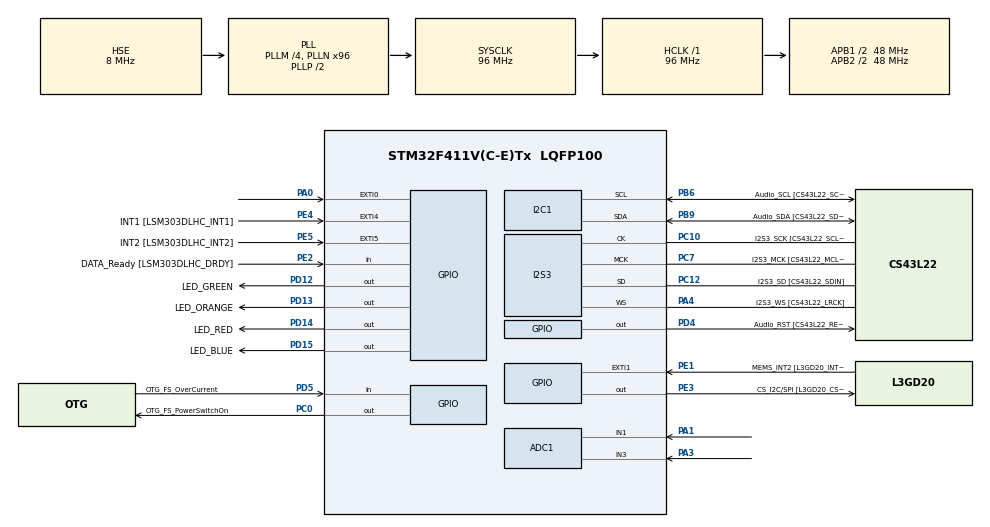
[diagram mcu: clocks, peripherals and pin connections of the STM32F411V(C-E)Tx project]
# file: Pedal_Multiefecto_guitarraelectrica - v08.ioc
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PD12.GPIO_Label=LED_GREEN
TIM2.Channel-Output\ Compare1\ No\ Output=TIM_CHANNEL_1
PC10.GPIO_PuPd=GPIO_NOPULL
PC12.Signal=I2S3_SD
PA14.GPIO_Label=SWCLK
PA6.GPIO_Label=SPI1_MISO [L3GD20_AS0/SDO]
PB6.GPIO_Label=Audio_SCL [CS43L22_SCL]
PC15-OSC32_OUT.GPIO_Label=PC15-OSC32_OUT
RCC.SYSCLKSource=RCC_SYSCLKSOURCE_PLLCLK
PD14.GPIO_Speed=GPIO_SPEED_FREQ_LOW
PA4.Mode=Half_Duplex_Master
RCC.APB2TimFreq_Value=96000000
PD4.Signal=GPIO_Output
Dma.ADC1.0.Direction=DMA_PERIPH_TO_MEMORY
PB6.Signal=I2C1_SCL
PC7.Signal=I2S3_MCK
PB6.Mode=I2C
PC3.Signal=I2S2_SD
PE5.Signal=GPXTI5
PE1.Signal=GPXTI1
Dma.ADC1.0.MemDataAlignment=DMA_MDATAALIGN_WORD
ADC1.ScanConvMode=ENABLE
I2S3.ErrorAudioFreq=0.0 %
Dma.ADC1.0.PeriphInc=DMA_PINC_DISABLE
NVIC.TIM2_IRQn=true\:0\:0\:false\:false\:true\:true\:true
PE4.GPIO_Label=INT1 [LSM303DLHC_INT1]
PE2.Signal=GPIO_Input
PD14.GPIO_PuPd=GPIO_NOPULL
ADC1.SamplingTime-0\#ChannelRegularConversion=ADC_SAMPLETIME_3CYCLES
Mcu.Package=LQFP100
PB9.Signal=I2C1_SDA
TIM2.Prescaler=1000-1
PD12.Signal=GPIO_Output
PA10.Signal=USB_OTG_FS_ID
PB9.GPIO_PuPd=GPIO_NOPULL
RCC.APB2CLKDivider=RCC_HCLK_DIV2
RCC.APB1TimFreq_Value=96000000
Dma.ADC1.0.FIFOMode=DMA_FIFOMODE_DISABLE
PC12.GPIO_PuPd=GPIO_NOPULL
PA4.GPIO_Label=I2S3_WS [CS43L22_LRCK]
ADC1.EOCSelection=ADC_EOC_SEQ_CONV
PD15.Signal=GPIO_Output
PC0.PinState=GPIO_PIN_SET
Dma.SPI3_TX.1.MemInc=DMA_MINC_ENABLE
I2S3.FullDuplexMode=I2S_FULLDUPLEXMODE_DISABLE
Dma.ADC1.0.Instance=DMA2_Stream0
ADC1.Rank-0\#ChannelRegularConversion=1
TIM3.Channel-Output\ Compare1\ No\ Output=TIM_CHANNEL_1
TIM3.AutoReloadPreload=TIM_AUTORELOAD_PRELOAD_ENABLE
PA9.GPIO_Label=VBUS_FS
PB6.GPIO_PuPd=GPIO_NOPULL
PH1\ -\ OSC_OUT.Mode=HSE-External-Oscillator
PA11.GPIO_Label=OTG_FS_DM
Dma.SPI3_TX.1.Priority=DMA_PRIORITY_LOW
PC0.Signal=GPIO_Output
RCC.APB1CLKDivider=RCC_HCLK_DIV2
PC14-OSC32_IN.Signal=RCC_OSC32_IN
I2S3.DataFormat=I2S_DATAFORMAT_16B_EXTENDED
PA0-WKUP.GPIO_ModeDefaultEXTI=GPIO_MODE_EVT_RISING
PA0-WKUP.Signal=GPXTI0
PC10.GPIO_Mode=GPIO_MODE_AF_PP
PE5.GPIO_ModeDefaultEXTI=GPIO_MODE_EVT_RISING
Dma.ADC1.0.Priority=DMA_PRIORITY_LOW
PA9.Signal=USB_OTG_FS_VBUS
Dma.SPI3_TX.1.MemDataAlignment=DMA_MDATAALIGN_WORD
I2S3.VirtualMode=I2S_MODE_MASTER
PC7.GPIO_PuPd=GPIO_NOPULL
PB10.Signal=I2S2_CK
PA5.Signal=SPI1_SCK
I2S3.AudioFreq=I2S_AUDIOFREQ_32K
PC12.Mode=Half_Duplex_Master
PH1\ -\ OSC_OUT.Signal=RCC_OSC_OUT
VP_TIM3_VS_no_output1.Mode=Output Compare1 No Output
PE1.GPIO_Label=MEMS_INT2 [L3GD20_INT2]
NVIC.TIM3_IRQn=true\:0\:0\:false\:false\:true\:true\:true
TIM3.OCMode_1=TIM_OCMODE_TIMING
ADC1.DMAContinuousRequests=ENABLE
TIM2.Period=96000-1
PA13.Mode=Serial_Wire
ADC1.ExternalTrigConv=ADC_EXTERNALTRIGCONV_T3_TRGO
PC7.GPIO_Label=I2S3_MCK [CS43L22_MCLK]
Dma.SPI3_TX.1.PeriphInc=DMA_PINC_DISABLE
PA4.Signal=I2S3_WS
PC12.GPIO_Mode=GPIO_MODE_AF_PP
ADC1.master=1
PA5.GPIO_Label=SPI1_SCK [L3GD20_SC/SPC]
PE5.GPIO_Label=INT2 [LSM303DLHC_INT2]
PC12.GPIO_Label=I2S3_SD [CS43L22_SDIN]
PA11.Signal=USB_OTG_FS_DM
ProjectManager.HeapSize=0x200
NVIC.PriorityGroup=NVIC_PRIORITYGROUP_0
PE3.Signal=GPIO_Output
TIM2.AutoReloadPreload=TIM_AUTORELOAD_PRELOAD_ENABLE
PC3.GPIO_Label=PDM_OUT [MP45DT02_DOUT]
I2S3.Instance=SPI$Index
PB6.GPIO_Speed=GPIO_SPEED_FREQ_LOW
Mcu.Family=STM32F4
RCC.CortexFreq_Value=96000000
PB6.GPIO_Mode=GPIO_MODE_AF_OD
ADC1.ContinuousConvMode=DISABLE
PD15.GPIO_Speed=GPIO_SPEED_FREQ_LOW
PC10.Signal=I2S3_CK
PC0.GPIO_Label=OTG_FS_PowerSwitchOn
PC10.GPIO_Speed=GPIO_SPEED_FREQ_LOW
ProjectManager.StackSize=0x400
PD13.Signal=GPIO_Output
PA12.Signal=USB_OTG_FS_DP
PH0\ -\ OSC_IN.Signal=RCC_OSC_IN
ADC1.Channel-3\#ChannelRegularConversion=ADC_CHANNEL_3
RCC.HCLKFreq_Value=96000000
SH.ADCx_IN3.0=ADC1_IN3,IN3
TIM3.Period=1500-1
TIM2.ClockDivision=TIM_CLOCKDIVISION_DIV1
NVIC.DMA2_Stream0_IRQn=true\:0\:0\:false\:false\:true\:false\:true
RCC.AHBFreq_Value=96000000
ADC1.Channel-0\#ChannelRegularConversion=ADC_CHANNEL_1
RCC.HSE_VALUE=8000000
VP_TIM2_VS_no_output1.Mode=Output Compare1 No Output
PA4.GPIO_PuPd=GPIO_NOPULL
PA4.GPIO_Speed=GPIO_SPEED_FREQ_LOW
PC14-OSC32_IN.Mode=LSE-External-Oscillator
PA14.Mode=Serial_Wire
TIM3.Prescaler=1-1
PA10.GPIO_Label=OTG_FS_ID
PC7.GPIO_Mode=GPIO_MODE_AF_PP
PE4.Signal=GPXTI4
PD13.GPIO_Label=LED_ORANGE
PA6.Signal=SPI1_MISO
PD5.GPIO_Label=OTG_FS_OverCurrent
PD15.GPIO_PuPd=GPIO_NOPULL
Dma.SPI3_TX.1.Direction=DMA_MEMORY_TO_PERIPH
SH.ADCx_IN1.0=ADC1_IN1,IN1
PB9.GPIO_Speed=GPIO_SPEED_FREQ_LOW
Dma.Request1=SPI3_TX
PC14-OSC32_IN.GPIO_Label=PC14-OSC32_IN
Dma.Request0=ADC1
PE2.GPIO_Label=DATA_Ready [LSM303DLHC_DRDY]
PA3.Signal=ADCx_IN3
PB3.GPIO_Label=SWO
RCC.PLLSourceVirtual=RCC_PLLSOURCE_HSE
PC15-OSC32_OUT.Mode=LSE-External-Oscillator
PD12.GPIO_Speed=GPIO_SPEED_FREQ_LOW
PD15.GPIO_Label=LED_BLUE
PB9.GPIO_Label=Audio_SDA [CS43L22_SDA]
PC10.GPIO_Label=I2S3_SCK [CS43L22_SCLK]
PC10.Mode=Half_Duplex_Master
PE4.GPIO_ModeDefaultEXTI=GPIO_MODE_EVT_RISING
Dma.SPI3_TX.1.FIFOMode=DMA_FIFOMODE_DISABLE
PD5.Signal=GPIO_Input
PE1.GPIO_ModeDefaultEXTI=GPIO_MODE_EVT_RISING
PA12.GPIO_Label=OTG_FS_DP
Dma.SPI3_TX.1.Instance=DMA1_Stream5
Dma.SPI3_TX.1.PeriphDataAlignment=DMA_PDATAALIGN_WORD
PA13.Signal=SYS_JTMS-SWDIO
Dma.ADC1.0.PeriphDataAlignment=DMA_PDATAALIGN_WORD
PH0\ -\ OSC_IN.Mode=HSE-External-Oscillator
Dma.SPI3_TX.1.Mode=DMA_CIRCULAR
ProjectManager.TargetToolchain=SW4STM32
PB10.GPIO_Label=CLK_IN [MP45DT02_CLK]
NVIC.DMA1_Stream5_IRQn=true\:0\:0\:false\:false\:true\:false\:true
Dma.ADC1.0.Mode=DMA_CIRCULAR
PB9.Mode=I2C
PC15-OSC32_OUT.Signal=RCC_OSC32_OUT
PA1.Signal=ADCx_IN1
board=STM32F411E-DISCO
PD13.GPIO_Speed=GPIO_SPEED_FREQ_LOW
PC7.GPIO_Speed=GPIO_SPEED_FREQ_LOW
RCC.VCOOutputFreq_Value=192000000
PB9.GPIO_Mode=GPIO_MODE_AF_OD
PA4.GPIO_Mode=GPIO_MODE_AF_PP
RCC.APB2Freq_Value=48000000
PD4.GPIO_Label=Audio_RST [CS43L22_RESET]
PD13.GPIO_PuPd=GPIO_NOPULL
PD14.GPIO_Label=LED_RED
ADC1.NbrOfConversion=2
Mcu.Name=STM32F411V(C-E)Tx
PA13.GPIO_Label=SWDIO
PH1\ -\ OSC_OUT.GPIO_Label=PH1-OSC_OUT
PD14.Signal=GPIO_Output
RCC.48MHZClocksFreq_Value=24000000
PB3.Signal=SYS_JTDO-SWO
RCC.SYSCLKFreq_VALUE=96000000
PA7.GPIO_Label=SPI1_MOSI [L3GD20_SDA/SDI/SDO]
ADC1.Rank-3\#ChannelRegularConversion=2
ADC1.SamplingTime-3\#ChannelRegularConversion=ADC_SAMPLETIME_3CYCLES
TIM3.TIM_MasterSlaveMode=TIM_MASTERSLAVEMODE_DISABLE
PA14.Signal=SYS_JTCK-SWCLK
Dma.ADC1.0.MemInc=DMA_MINC_ENABLE
RCC.HSI_VALUE=16000000
RCC.PLLQ=8
ADC1.NbrOfConversionFlag=1
I2S3.RealAudioFreq=32.001 KHz
RCC.PLLM=4
RCC.PLLN=96
PE3.GPIO_Label=CS_I2C/SPI [L3GD20_CS_I2C/SPI]
PH0\ -\ OSC_IN.GPIO_Label=PH0-OSC_IN
TIM3.TIM_MasterOutputTrigger=TIM_TRGO_UPDATE
PC7.Mode=Master_Clock_Activated
RCC.APB1Freq_Value=48000000
PC12.GPIO_Speed=GPIO_SPEED_FREQ_LOW
ADC1.ClockPrescaler=ADC_CLOCK_SYNC_PCLK_DIV2
RCC.PLLI2SN=213
PB12.Signal=I2S2_WS
PD12.GPIO_PuPd=GPIO_NOPULL
RCC.PLLI2SM=8
PA7.Signal=SPI1_MOSI

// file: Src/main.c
/* USER CODE BEGIN Header */
/**
  ******************************************************************************
  * @file           : main.c
  * @brief          : Main program body
  ******************************************************************************
  * @attention
  *
  * <h2><center>&copy; Copyright (c) 2020 STMicroelectronics.
  * All rights reserved.</center></h2>
  *
  * This software component is licensed by ST under Ultimate Liberty license
  * SLA0044, the "License"; You may not use this file except in compliance with
  * the License. You may obtain a copy of the License at:
  *                             www.st.com/SLA0044
  *
  ******************************************************************************
  */
/* USER CODE END Header */

#include "main.h"
#include "adc.h"
#include "dma.h"
#include "i2c.h"
#include "i2s.h"
#include "tim.h"
#include "gpio.h"

/* USER CODE BEGIN Includes */

#include "stm32f4xx_it.h"
#include "main_funcs.h"

/* USER CODE END Includes */

void SystemClock_Config(void);

#include "audio.h"
int main(void)
{

  /* MCU Configuration--------------------------------------------------------*/

  /* Reset of all peripherals, Initializes the Flash interface and the Systick. */
  HAL_Init();

  /* Configure the system clock */
  SystemClock_Config();

  /* USER CODE BEGIN SysInit */
  SystemCoreClockUpdate();
  uint32_t p1 = HAL_RCC_GetPCLK1Freq ();
  uint32_t p2 = HAL_RCC_GetPCLK2Freq ();

  if (p1 < 8 || p2 < 9)
  {
	  HardFault_Handler ();
  }
  /* USER CODE END SysInit */

  /* Initialize all configured peripherals */
  MX_GPIO_Init();
  MX_DMA_Init();
  MX_I2C1_Init();
  MX_I2S3_Init();
  MX_TIM2_Init();
  MX_ADC1_Init();
  MX_TIM3_Init();
  /* USER CODE BEGIN 2 */

  main_init ();

  /* USER CODE END 2 */

  /* Infinite loop */
  while (1)
  {

    /* USER CODE BEGIN 3 */
	  main_loop ();
  }
  /* USER CODE END 3 */
}

void SystemClock_Config(void)
{
  RCC_OscInitTypeDef RCC_OscInitStruct = {0};
  RCC_ClkInitTypeDef RCC_ClkInitStruct = {0};
  RCC_PeriphCLKInitTypeDef PeriphClkInitStruct = {0};

  /** Configure the main internal regulator output voltage
  */
  __HAL_RCC_PWR_CLK_ENABLE();
  __HAL_PWR_VOLTAGESCALING_CONFIG(PWR_REGULATOR_VOLTAGE_SCALE1);
  /** Initializes the CPU, AHB and APB busses clocks
  */
  RCC_OscInitStruct.OscillatorType = RCC_OSCILLATORTYPE_HSE;
  RCC_OscInitStruct.HSEState = RCC_HSE_ON;
  RCC_OscInitStruct.PLL.PLLState = RCC_PLL_ON;
  RCC_OscInitStruct.PLL.PLLSource = RCC_PLLSOURCE_HSE;
  RCC_OscInitStruct.PLL.PLLM = 4;
  RCC_OscInitStruct.PLL.PLLN = 96;
  RCC_OscInitStruct.PLL.PLLP = RCC_PLLP_DIV2;
  RCC_OscInitStruct.PLL.PLLQ = 8;
  if (HAL_RCC_OscConfig(&RCC_OscInitStruct) != HAL_OK)
  {
    Error_Handler();
  }
  /** Initializes the CPU, AHB and APB busses clocks
  */
  RCC_ClkInitStruct.ClockType = RCC_CLOCKTYPE_HCLK|RCC_CLOCKTYPE_SYSCLK
                              |RCC_CLOCKTYPE_PCLK1|RCC_CLOCKTYPE_PCLK2;
  RCC_ClkInitStruct.SYSCLKSource = RCC_SYSCLKSOURCE_PLLCLK;
  RCC_ClkInitStruct.AHBCLKDivider = RCC_SYSCLK_DIV1;
  RCC_ClkInitStruct.APB1CLKDivider = RCC_HCLK_DIV2;
  RCC_ClkInitStruct.APB2CLKDivider = RCC_HCLK_DIV2;

  if (HAL_RCC_ClockConfig(&RCC_ClkInitStruct, FLASH_LATENCY_3) != HAL_OK)
  {
    Error_Handler();
  }
  PeriphClkInitStruct.PeriphClockSelection = RCC_PERIPHCLK_I2S;
  PeriphClkInitStruct.PLLI2S.PLLI2SN = 213;
  PeriphClkInitStruct.PLLI2S.PLLI2SM = 8;
  PeriphClkInitStruct.PLLI2S.PLLI2SR = 2;
  if (HAL_RCCEx_PeriphCLKConfig(&PeriphClkInitStruct) != HAL_OK)
  {
    Error_Handler();
  }
}

void Error_Handler(void)
{
}

/************************ (C) COPYRIGHT STMicroelectronics *****END OF FILE****/
